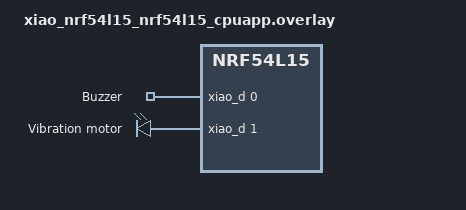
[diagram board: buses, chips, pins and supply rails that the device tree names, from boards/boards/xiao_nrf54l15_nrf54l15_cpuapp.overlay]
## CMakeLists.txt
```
#
# Copyright (c) 2024 Nordic Semiconductor ASA
#
# SPDX-License-Identifier: LicenseRef-Nordic-5-Clause
#
cmake_minimum_required(VERSION 3.20.0)

find_package(Zephyr REQUIRED HINTS $ENV{ZEPHYR_BASE})
project(Emretag)

# NORDIC SDK APP START
target_sources(app PRIVATE
  src/main.c
  src/outputs.c
  src/button.c
  src/imu.c
  src/app_gatt.c
  src/ble_cs.c
)
# NORDIC SDK APP END
```

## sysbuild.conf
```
# MCUboot as an immutable first-stage bootloader.
SB_CONFIG_BOOTLOADER_MCUBOOT=y

# ED25519 over SHA-256. The nRF54L15 has hardware support for it, and it keeps
# the signature small compared with RSA.
SB_CONFIG_BOOT_SIGNATURE_TYPE_ED25519=y

# Swap-using-move keeps the previous image in the other slot, which is what
# makes revert possible: an image that boots but is never confirmed is rolled
# back on the next reset. Overwrite-only would delete the old image and there
# would be nothing to fall back to.
SB_CONFIG_MCUBOOT_MODE_SWAP_USING_MOVE=y

# Until a real key is generated, the build falls back to the MCUboot sample key
# that ships with the SDK - which is public, so it authenticates nothing.
# Generate a private key and point this at it before flashing anything that
# matters:
#
#   imgtool keygen -k mcuboot_signing_key.pem -t ed25519
#
# then uncomment, and keep the .pem out of the repository.
#
# SB_CONFIG_BOOT_SIGNATURE_KEY_FILE="mcuboot_signing_key.pem"
```

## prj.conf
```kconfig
#
# Copyright (c) 2024 Nordic Semiconductor ASA
#
# SPDX-License-Identifier: LicenseRef-Nordic-5-Clause
#

CONFIG_NCS_SAMPLES_DEFAULTS=y
CONFIG_DK_LIBRARY=y

CONFIG_BT=y
CONFIG_BT_PERIPHERAL=y
CONFIG_BT_SMP=y
CONFIG_BT_DEVICE_NAME="EmreTag"
CONFIG_BT_MAX_CONN=1
CONFIG_BT_GAP_AUTO_UPDATE_CONN_PARAMS=n
CONFIG_BT_BONDABLE=n

# The Ranging Profile recommends a MTU of at least 247 octets.
CONFIG_BT_L2CAP_TX_MTU=498
CONFIG_BT_BUF_ACL_TX_SIZE=502
CONFIG_BT_BUF_ACL_RX_SIZE=502
CONFIG_BT_CTLR_DATA_LENGTH_MAX=251
CONFIG_BT_CTLR_PHY_2M=y

# This reduces RAM usage. Additional RAM is needed to support optional
# features such as mode 3 or multiantenna. Change or remove these if
# using those features
CONFIG_BT_RAS_MODE_3_SUPPORTED=n
CONFIG_BT_RAS_MAX_ANTENNA_PATHS=1
CONFIG_BT_CS_DE_MAX_NUM_ANTENNA_PATHS=1
CONFIG_BT_CTLR_SDC_CS_MAX_ANTENNA_PATHS=1
CONFIG_BT_CTLR_SDC_CS_NUM_ANTENNAS=1
CONFIG_BT_CTLR_SDC_CS_STEP_MODE3=n
CONFIG_BT_CTLR_SDC_CS_ROLE_REFLECTOR_ONLY=y

# Disabling the CS Test command reduces flash usage
CONFIG_BT_CTLR_CHANNEL_SOUNDING_TEST=n

# This allows CS and ACL to use different PHYs
CONFIG_BT_TRANSMIT_POWER_CONTROL=y

# Let the initiating device control the PHY updates
CONFIG_BT_AUTO_PHY_UPDATE=n

CONFIG_BT_CHANNEL_SOUNDING=y
CONFIG_BT_RAS=y
CONFIG_BT_RAS_RRSP=y

# IMU. The onboard LSM6DS3TR-C is driven by the LSM6DSL driver (see the
# "st,lsm6dsl" compatible in the board DTS). The driver selects I2C itself.
CONFIG_SENSOR=y
CONFIG_LSM6DSL=y
# Poll the sensor instead of using its INT pin.
CONFIG_LSM6DSL_TRIGGER_NONE=y
# The driver defaults are 0 ("selected at runtime"), which leaves the sensor
# powered down and every reading at zero. 4 = 104 Hz.
CONFIG_LSM6DSL_ACCEL_ODR=4
CONFIG_LSM6DSL_ACCEL_FS=2
CONFIG_LSM6DSL_GYRO_ODR=4
CONFIG_LSM6DSL_GYRO_FS=250

# Required for the %f conversions in the IMU log output.
CONFIG_CBPRINTF_FP_SUPPORT=y

# --- Firmware update over BLE (SMP / MCUmgr): currently disabled ---
#
# Belongs together with the MCUboot block in sysbuild.conf - image upload is
# pointless without a bootloader to hand the new image to. Re-enable both.
#
# CONFIG_MCUMGR=y
# CONFIG_MCUMGR_TRANSPORT_BT=y
#
# With CONFIG_BT_SMP the SMP service defaults to requiring an encrypted and
# authenticated link, which this application cannot provide because it does not
# bond (CONFIG_BT_BONDABLE=n). Left at the default, every DFU attempt fails with
# an ATT authentication error - an hour lost to a symptom that never names its
# cause. Open access is acceptable on a bench device because MCUboot still
# refuses anything not signed with the right key; a shipping product should bond
# and put this back to RW_AUTHEN so the link is trusted too.
#
# CONFIG_MCUMGR_TRANSPORT_BT_PERM_RW=y
# CONFIG_MCUMGR_TRANSPORT_BT_CONN_PARAM_CONTROL=y
#
# CONFIG_MCUMGR_GRP_IMG=y
# CONFIG_MCUMGR_GRP_OS=y
# CONFIG_MCUMGR_GRP_OS_MCUMGR_PARAMS=y
#
# CONFIG_FLASH=y
# CONFIG_FLASH_MAP=y
# CONFIG_STREAM_FLASH=y
# CONFIG_IMG_MANAGER=y
# CONFIG_IMG_ERASE_PROGRESSIVELY=y
# CONFIG_MCUBOOT_IMG_MANAGER=y
```

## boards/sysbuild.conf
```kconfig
# --- Secure boot and DFU: currently disabled ---
#
# Re-enable together with the MCUmgr block in prj.conf; neither half is useful
# on its own. A pristine build is needed either way, because sysbuild only
# collects this file at configure time:
#
#   west build -b xiao_nrf54l15/nrf54l15/cpuapp -p always
#
# MCUboot as an immutable first-stage bootloader:
#
# SB_CONFIG_BOOTLOADER_MCUBOOT=y
#
# ED25519 over SHA-256. The nRF54L15 has hardware support for it, and the
# signature is small compared with RSA.
#
# SB_CONFIG_BOOT_SIGNATURE_TYPE_ED25519=y
#
# Swap-using-move keeps the previous image in the other slot, which is what
# makes revert possible: an image that boots but is never confirmed is rolled
# back on the next reset. Overwrite-only would delete the old image and there
# would be nothing to fall back to.
#
# SB_CONFIG_MCUBOOT_MODE_SWAP_USING_MOVE=y
#
# Without a key file the build falls back to the MCUboot sample key that ships
# with the SDK - which is public, so it authenticates nothing. Generate one and
# keep the .pem out of the repository:
#
#   imgtool keygen -k mcuboot_signing_key.pem -t ed25519
#
# SB_CONFIG_BOOT_SIGNATURE_KEY_FILE="mcuboot_signing_key.pem"
```

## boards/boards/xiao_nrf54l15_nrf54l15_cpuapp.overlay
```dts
/*
 * Buzzer and vibration motor. The board devicetree does not describe them, so
 * the tag adds them here.
 *
 * Pins are XIAO connector numbers (D0..D15), mapped in
 * seeed_xiao_connector.dtsi. CHANGE THESE TO MATCH YOUR WIRING - D0 and D1 are
 * placeholders. Check before using D6..D10 or D13..D15: those land on gpio2,
 * which also carries the LED (pin 0) and the RF switch (pins 3 and 5).
 *
 * Use GPIO_ACTIVE_LOW instead of GPIO_ACTIVE_HIGH if the driver transistor
 * turns the load on when the pin is pulled low. Nothing in the C code needs to
 * change; gpio_pin_set_dt() works in logical levels.
 *
 * "gpio-leds" is used as the compatible because it is Zephyr's generic binding
 * for a set of GPIO outputs - it is not saying these are LEDs.
 */

/ {
	tag_outputs {
		compatible = "gpio-leds";

		buzzer: buzzer {
			gpios = <&xiao_d 0 GPIO_ACTIVE_HIGH>;	/* D0 -> P1.04 */
			label = "Buzzer";
		};

		vibration_motor: vibration-motor {
			gpios = <&xiao_d 1 GPIO_ACTIVE_HIGH>;	/* D1 -> P1.05 */
			label = "Vibration motor";
		};
	};

	aliases {
		buzzer = &buzzer;
		vibration-motor = &vibration_motor;
	};
};
```

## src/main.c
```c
/*
 * Copyright (c) 2024 Nordic Semiconductor ASA
 *
 * SPDX-License-Identifier: LicenseRef-Nordic-5-Clause
 */

/** @file
 *  @brief EmreTag - Channel Sounding reflector with Ranging Responder.
 *
 *  Only the start-up order lives here. Drivers sit in imu.c, button.c and
 *  outputs.c; the link and the Channel Sounding role in ble_cs.c; the
 *  application - the profile and what the tag does - in app_gatt.c.
 */

#include <zephyr/kernel.h>
#include <zephyr/logging/log.h>

#include "app_gatt.h"
#include "ble_cs.h"
#include "outputs.h"

LOG_MODULE_REGISTER(app_main, LOG_LEVEL_INF);

int main(void)
{
	int err;

	LOG_INF("Starting EmreTag - Channel Sounding reflector");

	err = outputs_init();
	if (err) {
		return -1;
	}

	/* Selects the antenna path before bringing the radio up. */
	err = ble_cs_start();
	if (err) {
		return -1;
	}

	/* After advertising is up: from here a button press or a tap can reach
	 * the Bluetooth stack.
	 */
	err = app_gatt_init();
	if (err) {
		return -1;
	}

	ble_cs_run();

	return 0;
}
```

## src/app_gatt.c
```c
/*
 * SPDX-License-Identifier: LicenseRef-Nordic-5-Clause
 */

#include <zephyr/kernel.h>
#include <zephyr/bluetooth/bluetooth.h>
#include <zephyr/bluetooth/gatt.h>
#include <zephyr/bluetooth/uuid.h>
#include <zephyr/logging/log.h>

#include "app_gatt.h"
#include "button.h"
#include "outputs.h"

LOG_MODULE_REGISTER(app_gatt, LOG_LEVEL_INF);

/* Built on the Nordic LED Button Service UUIDs so that nRF Connect and nRF
 * Toolbox recognise the first three characteristics out of the box; the buzzer
 * and vibration motor continue the same series.
 */
#define BT_UUID_BTN_SVC_VAL                                                                        \
	BT_UUID_128_ENCODE(0x00001523, 0x1212, 0xefde, 0x1523, 0x785feabcd123)
#define BT_UUID_BTN_CHRC_VAL                                                                       \
	BT_UUID_128_ENCODE(0x00001524, 0x1212, 0xefde, 0x1523, 0x785feabcd123)
#define BT_UUID_LED_CHRC_VAL                                                                       \
	BT_UUID_128_ENCODE(0x00001525, 0x1212, 0xefde, 0x1523, 0x785feabcd123)
#define BT_UUID_BUZZER_CHRC_VAL                                                                    \
	BT_UUID_128_ENCODE(0x00001526, 0x1212, 0xefde, 0x1523, 0x785feabcd123)
#define BT_UUID_VIB_CHRC_VAL                                                                       \
	BT_UUID_128_ENCODE(0x00001527, 0x1212, 0xefde, 0x1523, 0x785feabcd123)
#define BT_UUID_FIND_PHONE_CHRC_VAL                                                                \
	BT_UUID_128_ENCODE(0x00001528, 0x1212, 0xefde, 0x1523, 0x785feabcd123)
#define BT_UUID_FALL_CHRC_VAL                                                                      \
	BT_UUID_128_ENCODE(0x00001529, 0x1212, 0xefde, 0x1523, 0x785feabcd123)

#define BT_UUID_BTN_SVC     BT_UUID_DECLARE_128(BT_UUID_BTN_SVC_VAL)
#define BT_UUID_BTN_CHRC    BT_UUID_DECLARE_128(BT_UUID_BTN_CHRC_VAL)
#define BT_UUID_LED_CHRC    BT_UUID_DECLARE_128(BT_UUID_LED_CHRC_VAL)
#define BT_UUID_BUZZER_CHRC BT_UUID_DECLARE_128(BT_UUID_BUZZER_CHRC_VAL)
#define BT_UUID_VIB_CHRC    BT_UUID_DECLARE_128(BT_UUID_VIB_CHRC_VAL)
#define BT_UUID_FIND_PHONE_CHRC BT_UUID_DECLARE_128(BT_UUID_FIND_PHONE_CHRC_VAL)
#define BT_UUID_FALL_CHRC	BT_UUID_DECLARE_128(BT_UUID_FALL_CHRC_VAL)

/* Backing store for the button characteristic value. Kept in sync from the
 * notify path so a plain read returns the current level too.
 */
static uint8_t button_value;
static bool button_notify_enabled;

/* Incremented every time the user asks for the phone. Readable as well as
 * notified, so a client that reconnects can see whether it missed anything.
 */
static uint8_t find_phone_count;
static bool find_phone_notify_enabled;

static ssize_t read_button(struct bt_conn *conn, const struct bt_gatt_attr *attr, void *buf,
			   uint16_t len, uint16_t offset)
{
	button_value = button_get_state();

	return bt_gatt_attr_read(conn, attr, buf, len, offset, &button_value,
				 sizeof(button_value));
}

static void button_ccc_cfg_changed(const struct bt_gatt_attr *attr, uint16_t value)
{
	ARG_UNUSED(attr);

	button_notify_enabled = (value == BT_GATT_CCC_NOTIFY);
	LOG_INF("Button notifications %s", button_notify_enabled ? "enabled" : "disabled");
}

static ssize_t read_find_phone(struct bt_conn *conn, const struct bt_gatt_attr *attr, void *buf,
			       uint16_t len, uint16_t offset)
{
	return bt_gatt_attr_read(conn, attr, buf, len, offset, &find_phone_count,
				 sizeof(find_phone_count));
}

/* Same shape as the find-phone counter: raised by the tag, cleared by the peer. */
static uint8_t fall_count;
static bool fall_notify_enabled;
static app_gatt_fall_cleared_cb_t fall_cleared_cb;

/* Defined below the service, which they have to reference. */
static void find_phone_notify_work_handler(struct k_work *work);
static void fall_notify_work_handler(struct k_work *work);

static K_WORK_DEFINE(find_phone_notify_work, find_phone_notify_work_handler);
static K_WORK_DEFINE(fall_notify_work, fall_notify_work_handler);

static ssize_t read_fall(struct bt_conn *conn, const struct bt_gatt_attr *attr, void *buf,
			 uint16_t len, uint16_t offset)
{
	return bt_gatt_attr_read(conn, attr, buf, len, offset, &fall_count, sizeof(fall_count));
}

static ssize_t write_fall(struct bt_conn *conn, const struct bt_gatt_attr *attr, const void *buf,
			  uint16_t len, uint16_t offset, uint8_t flags)
{
	ARG_UNUSED(conn);
	ARG_UNUSED(attr);
	ARG_UNUSED(flags);

	if (offset != 0) {
		return BT_GATT_ERR(BT_ATT_ERR_INVALID_OFFSET);
	}

	if (len != sizeof(fall_count)) {
		return BT_GATT_ERR(BT_ATT_ERR_INVALID_ATTRIBUTE_LEN);
	}

	if (((const uint8_t *)buf)[0] != 0) {
		return BT_GATT_ERR(BT_ATT_ERR_VALUE_NOT_ALLOWED);
	}

	fall_count = 0;
	LOG_INF("Fall alarm cleared by peer");

	if (fall_cleared_cb) {
		fall_cleared_cb();
	}

	k_work_submit(&fall_notify_work);

	return len;
}

static void fall_ccc_cfg_changed(const struct bt_gatt_attr *attr, uint16_t value)
{
	ARG_UNUSED(attr);

	fall_notify_enabled = (value == BT_GATT_CCC_NOTIFY);
	LOG_INF("Fall notifications %s", fall_notify_enabled ? "enabled" : "disabled");
}

/* The phone writes 0 to say it has handled - or dismissed - the request, which
 * clears the counter. Any other value is refused, so the count can only ever be
 * raised by the tag itself.
 */
static ssize_t write_find_phone(struct bt_conn *conn, const struct bt_gatt_attr *attr,
				const void *buf, uint16_t len, uint16_t offset, uint8_t flags)
{
	ARG_UNUSED(conn);
	ARG_UNUSED(attr);
	ARG_UNUSED(flags);

	if (offset != 0) {
		return BT_GATT_ERR(BT_ATT_ERR_INVALID_OFFSET);
	}

	if (len != sizeof(find_phone_count)) {
		return BT_GATT_ERR(BT_ATT_ERR_INVALID_ATTRIBUTE_LEN);
	}

	if (((const uint8_t *)buf)[0] != 0) {
		return BT_GATT_ERR(BT_ATT_ERR_VALUE_NOT_ALLOWED);
	}

	find_phone_count = 0;
	LOG_INF("Find-phone cancelled by peer");

	/* Push the cleared value out, otherwise a client that follows the
	 * characteristic through notifications keeps showing the old count until
	 * it happens to read again. Deferred, so the write response goes out
	 * before the notification.
	 */
	k_work_submit(&find_phone_notify_work);

	return len;
}

static void find_phone_ccc_cfg_changed(const struct bt_gatt_attr *attr, uint16_t value)
{
	ARG_UNUSED(attr);

	find_phone_notify_enabled = (value == BT_GATT_CCC_NOTIFY);
	LOG_INF("Find-phone notifications %s", find_phone_notify_enabled ? "enabled" : "disabled");
}

static ssize_t read_output(struct bt_conn *conn, const struct bt_gatt_attr *attr, void *buf,
			   uint16_t len, uint16_t offset)
{
	const struct gpio_output *out = attr->user_data;

	return bt_gatt_attr_read(conn, attr, buf, len, offset, &out->state, sizeof(out->state));
}

static ssize_t write_output(struct bt_conn *conn, const struct bt_gatt_attr *attr, const void *buf,
			    uint16_t len, uint16_t offset, uint8_t flags)
{
	struct gpio_output *out = attr->user_data;

	ARG_UNUSED(conn);
	ARG_UNUSED(flags);

	if (offset != 0) {
		return BT_GATT_ERR(BT_ATT_ERR_INVALID_OFFSET);
	}

	if (len != sizeof(out->state)) {
		return BT_GATT_ERR(BT_ATT_ERR_INVALID_ATTRIBUTE_LEN);
	}

	outputs_set(out, ((const uint8_t *)buf)[0]);

	LOG_INF("%s set to %u by peer", out->name, out->state);

	return len;
}

/* Each characteristic carries a User Description descriptor (0x2901) so that a
 * generic GATT client shows a name instead of just the 128-bit UUID. The button
 * value stays at attrs[2] - descriptors are appended after it, never before.
 */
BT_GATT_SERVICE_DEFINE(app_svc,
	BT_GATT_PRIMARY_SERVICE(BT_UUID_BTN_SVC),

	BT_GATT_CHARACTERISTIC(BT_UUID_BTN_CHRC,
			       BT_GATT_CHRC_READ | BT_GATT_CHRC_NOTIFY,
			       BT_GATT_PERM_READ,
			       read_button, NULL, &button_value),
	BT_GATT_CCC(button_ccc_cfg_changed, BT_GATT_PERM_READ | BT_GATT_PERM_WRITE),
	BT_GATT_CUD("Button", BT_GATT_PERM_READ),

	BT_GATT_CHARACTERISTIC(BT_UUID_LED_CHRC,
			       BT_GATT_CHRC_READ | BT_GATT_CHRC_WRITE,
			       BT_GATT_PERM_READ | BT_GATT_PERM_WRITE,
			       read_output, write_output, &led),
	BT_GATT_CUD("LED", BT_GATT_PERM_READ),

	BT_GATT_CHARACTERISTIC(BT_UUID_BUZZER_CHRC,
			       BT_GATT_CHRC_READ | BT_GATT_CHRC_WRITE,
			       BT_GATT_PERM_READ | BT_GATT_PERM_WRITE,
			       read_output, write_output, &buzzer),
	BT_GATT_CUD("Buzzer", BT_GATT_PERM_READ),

	BT_GATT_CHARACTERISTIC(BT_UUID_VIB_CHRC,
			       BT_GATT_CHRC_READ | BT_GATT_CHRC_WRITE,
			       BT_GATT_PERM_READ | BT_GATT_PERM_WRITE,
			       read_output, write_output, &vibration_motor),
	BT_GATT_CUD("Vibration motor", BT_GATT_PERM_READ),

	BT_GATT_CHARACTERISTIC(BT_UUID_FIND_PHONE_CHRC,
			       BT_GATT_CHRC_READ | BT_GATT_CHRC_WRITE | BT_GATT_CHRC_NOTIFY,
			       BT_GATT_PERM_READ | BT_GATT_PERM_WRITE,
			       read_find_phone, write_find_phone, &find_phone_count),
	BT_GATT_CCC(find_phone_ccc_cfg_changed, BT_GATT_PERM_READ | BT_GATT_PERM_WRITE),
	BT_GATT_CUD("Find phone", BT_GATT_PERM_READ),

	BT_GATT_CHARACTERISTIC(BT_UUID_FALL_CHRC,
			       BT_GATT_CHRC_READ | BT_GATT_CHRC_WRITE | BT_GATT_CHRC_NOTIFY,
			       BT_GATT_PERM_READ | BT_GATT_PERM_WRITE,
			       read_fall, write_fall, &fall_count),
	BT_GATT_CCC(fall_ccc_cfg_changed, BT_GATT_PERM_READ | BT_GATT_PERM_WRITE),
	BT_GATT_CUD("Fall detected", BT_GATT_PERM_READ),
);

int app_gatt_notify_button(uint8_t state)
{
	if (!button_notify_enabled) {
		return 0;
	}

	button_value = state;

	/* attrs[2] is the button characteristic value attribute. */
	return bt_gatt_notify(NULL, &app_svc.attrs[2], &button_value, sizeof(button_value));
}

/* Sends whatever the counter currently holds to a subscribed client. */
static int notify_find_phone_value(void)
{
	const struct bt_gatt_attr *attr;

	if (!find_phone_notify_enabled) {
		return 0;
	}

	/* Looked up rather than indexed, so inserting characteristics above it
	 * cannot silently point this at the wrong attribute.
	 */
	attr = bt_gatt_find_by_uuid(app_svc.attrs, app_svc.attr_count, BT_UUID_FIND_PHONE_CHRC);
	if (!attr) {
		return -ENOENT;
	}

	return bt_gatt_notify(NULL, attr, &find_phone_count, sizeof(find_phone_count));
}

static void find_phone_notify_work_handler(struct k_work *work)
{
	int err;

	ARG_UNUSED(work);

	err = notify_find_phone_value();
	if (err) {
		LOG_WRN("Failed to notify find-phone value (err %d)", err);
	}
}

int app_gatt_notify_find_phone(void)
{
	find_phone_count++;

	return notify_find_phone_value();
}

static int notify_fall_value(void)
{
	const struct bt_gatt_attr *attr;

	if (!fall_notify_enabled) {
		return 0;
	}

	attr = bt_gatt_find_by_uuid(app_svc.attrs, app_svc.attr_count, BT_UUID_FALL_CHRC);
	if (!attr) {
		return -ENOENT;
	}

	return bt_gatt_notify(NULL, attr, &fall_count, sizeof(fall_count));
}

static void fall_notify_work_handler(struct k_work *work)
{
	int err;

	ARG_UNUSED(work);

	err = notify_fall_value();
	if (err) {
		LOG_WRN("Failed to notify fall value (err %d)", err);
	}
}

void app_gatt_set_fall_cleared_cb(app_gatt_fall_cleared_cb_t cb)
{
	fall_cleared_cb = cb;
}

int app_gatt_notify_fall(void)
{
	fall_count++;

	return notify_fall_value();
}
```

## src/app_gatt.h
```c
/*
 * SPDX-License-Identifier: LicenseRef-Nordic-5-Clause
 */

/** @file
 *  @brief Application GATT service - button state in, output control out.
 *
 *  Distance values are not carried here; those go over the Ranging Service
 *  (RAS) provided by the nRF Connect SDK.
 */

#ifndef APP_GATT_H_
#define APP_GATT_H_

#include <stdint.h>

/** Notify the subscribed peer of a new button state.
 *
 *  Sends an HCI command and can block, so do not call from interrupt context.
 *  A no-op when no client has enabled notifications.
 */
int app_gatt_notify_button(uint8_t state);

/** Ask the connected phone to make itself findable.
 *
 *  Bumps a counter and notifies it, so a client can also see how many requests
 *  it missed. The phone clears the counter back to zero by writing 0 to the
 *  characteristic once it has handled or dismissed the request.
 *
 *  Sends an HCI command and can block; not for interrupt context.
 */
int app_gatt_notify_find_phone(void);

/** Called from the Bluetooth thread when the peer clears the fall alarm. */
typedef void (*app_gatt_fall_cleared_cb_t)(void);

/** Register who should be told that the peer cleared the fall alarm. */
void app_gatt_set_fall_cleared_cb(app_gatt_fall_cleared_cb_t cb);

/** Report that the tag has been dropped.
 *
 *  Same shape as the find-phone characteristic: a counter the peer clears by
 *  writing 0, which also stops the local alarm.
 */
int app_gatt_notify_fall(void);

#endif /* APP_GATT_H_ */
```

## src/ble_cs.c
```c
/*
 * SPDX-License-Identifier: LicenseRef-Nordic-5-Clause
 */

#include <zephyr/kernel.h>
#include <zephyr/bluetooth/bluetooth.h>
#include <zephyr/bluetooth/conn.h>
#include <zephyr/bluetooth/cs.h>
#include <zephyr/bluetooth/gap.h>
#include <zephyr/bluetooth/uuid.h>
#include <zephyr/settings/settings.h>
#include <zephyr/sys/byteorder.h>
#include <zephyr/sys/reboot.h>
#include <zephyr/logging/log.h>

#include <bluetooth/services/ras.h>

#include "ble_cs.h"
#include "outputs.h"

LOG_MODULE_REGISTER(ble_cs, LOG_LEVEL_INF);

#define COMPANY_ID_CODE 0x0059

static K_SEM_DEFINE(sem_connected, 0, 1);
static K_SEM_DEFINE(sem_config, 0, 1);

static struct bt_conn *connection;

struct adv_mfg_data {
	uint16_t company_code;	/* Company Identifier Code. */
	uint16_t number_press;	/* Number of times the button was pressed. */
};

static struct adv_mfg_data adv_mfg_data = { COMPANY_ID_CODE, 0x00 };

static const struct bt_data ad[] = {
	BT_DATA_BYTES(BT_DATA_FLAGS, (BT_LE_AD_GENERAL | BT_LE_AD_NO_BREDR)),
	BT_DATA_BYTES(BT_DATA_UUID16_ALL, BT_UUID_16_ENCODE(BT_UUID_RANGING_SERVICE_VAL)),
	BT_DATA(BT_DATA_NAME_COMPLETE, CONFIG_BT_DEVICE_NAME, sizeof(CONFIG_BT_DEVICE_NAME) - 1),
	BT_DATA(BT_DATA_MANUFACTURER_DATA, (unsigned char *)&adv_mfg_data, sizeof(adv_mfg_data)),
};

/* 0x17 is the "https://" URI scheme prefix. */
static const unsigned char url_data[] = { 0x17, '/', '/', 'g', 'i', 't', 'h', 'u', 'b', '.', 'c',
					  'o', 'm', '/', 'E', 'm', 'r', 'e', 'c', 'a', 'n', 'b',
					  'l' };

static const struct bt_data sd[] = {
	BT_DATA(BT_DATA_URI, url_data, sizeof(url_data)),
};

static void connected_cb(struct bt_conn *conn, uint8_t err)
{
	char addr[BT_ADDR_LE_STR_LEN];

	(void)bt_addr_le_to_str(bt_conn_get_dst(conn), addr, sizeof(addr));
	LOG_INF("Connected to %s (err 0x%02X)", addr, err);

	if (err) {
		bt_conn_unref(conn);
		connection = NULL;
	} else {
		connection = bt_conn_ref(conn);

		k_sem_give(&sem_connected);

		outputs_set(&led, 1);
	}
}

static void disconnected_cb(struct bt_conn *conn, uint8_t reason)
{
	LOG_INF("Disconnected (reason 0x%02X)", reason);

	bt_conn_unref(conn);
	connection = NULL;

	outputs_set(&led, 0);

	/* Inherited from the upstream Channel Sounding sample: a cold reboot
	 * sidesteps tearing the CS state down by hand. Incompatible with the
	 * low-power design and has to go once teardown is handled properly.
	 */
	sys_reboot(SYS_REBOOT_COLD);
}

static void remote_capabilities_cb(struct bt_conn *conn, uint8_t status,
				   struct bt_conn_le_cs_capabilities *params)
{
	ARG_UNUSED(conn);
	ARG_UNUSED(params);

	if (status == BT_HCI_ERR_SUCCESS) {
		LOG_INF("CS capability exchange completed.");
	} else {
		LOG_WRN("CS capability exchange failed. (HCI status 0x%02x)", status);
	}
}

static void config_create_cb(struct bt_conn *conn, uint8_t status,
			     struct bt_conn_le_cs_config *config)
{
	ARG_UNUSED(conn);

	if (status != BT_HCI_ERR_SUCCESS) {
		LOG_WRN("CS config creation failed. (HCI status 0x%02x)", status);
		return;
	}

	const char *mode_str[5] = { "Unused", "1 (RTT)", "2 (PBR)", "3 (RTT + PBR)", "Invalid" };
	const char *role_str[3] = { "Initiator", "Reflector", "Invalid" };
	const char *rtt_type_str[8] = { "AA only",	 "32-bit sounding", "96-bit sounding",
					"32-bit random", "64-bit random",   "96-bit random",
					"128-bit random", "Invalid" };
	const char *phy_str[4] = { "Invalid", "LE 1M PHY", "LE 2M PHY", "LE 2M 2BT PHY" };
	const char *chsel_type_str[3] = { "Algorithm #3b", "Algorithm #3c", "Invalid" };
	const char *ch3c_shape_str[3] = { "Hat shape", "X shape", "Invalid" };

	uint8_t mode_idx = config->mode > 0 && config->mode < 4 ? config->mode : 4;
	uint8_t role_idx = MIN(config->role, 2);
	uint8_t rtt_type_idx = MIN(config->rtt_type, 7);
	uint8_t phy_idx = config->cs_sync_phy > 0 && config->cs_sync_phy < 4 ? config->cs_sync_phy
									    : 0;
	uint8_t chsel_type_idx = MIN(config->channel_selection_type, 2);
	uint8_t ch3c_shape_idx = MIN(config->ch3c_shape, 2);

	LOG_INF("CS config creation complete.\n"
		" - id: %u\n"
		" - mode: %s\n"
		" - min_main_mode_steps: %u\n"
		" - max_main_mode_steps: %u\n"
		" - main_mode_repetition: %u\n"
		" - mode_0_steps: %u\n"
		" - role: %s\n"
		" - rtt_type: %s\n"
		" - cs_sync_phy: %s\n"
		" - channel_map_repetition: %u\n"
		" - channel_selection_type: %s\n"
		" - ch3c_shape: %s\n"
		" - ch3c_jump: %u\n"
		" - t_ip1_time_us: %u\n"
		" - t_ip2_time_us: %u\n"
		" - t_fcs_time_us: %u\n"
		" - t_pm_time_us: %u\n"
		" - channel_map: 0x%08X%08X%04X\n",
		config->id, mode_str[mode_idx], config->min_main_mode_steps,
		config->max_main_mode_steps, config->main_mode_repetition, config->mode_0_steps,
		role_str[role_idx], rtt_type_str[rtt_type_idx], phy_str[phy_idx],
		config->channel_map_repetition, chsel_type_str[chsel_type_idx],
		ch3c_shape_str[ch3c_shape_idx], config->ch3c_jump, config->t_ip1_time_us,
		config->t_ip2_time_us, config->t_fcs_time_us, config->t_pm_time_us,
		sys_get_le32(&config->channel_map[6]), sys_get_le32(&config->channel_map[2]),
		sys_get_le16(&config->channel_map[0]));

	k_sem_give(&sem_config);
}

static void security_enable_cb(struct bt_conn *conn, uint8_t status)
{
	ARG_UNUSED(conn);

	if (status == BT_HCI_ERR_SUCCESS) {
		LOG_INF("CS security enabled.");
	} else {
		LOG_WRN("CS security enable failed. (HCI status 0x%02x)", status);
	}
}

static void procedure_enable_cb(struct bt_conn *conn, uint8_t status,
				struct bt_conn_le_cs_procedure_enable_complete *params)
{
	ARG_UNUSED(conn);

	if (status != BT_HCI_ERR_SUCCESS) {
		LOG_WRN("CS procedures enable failed. (HCI status 0x%02x)", status);
		return;
	}

	if (params->state != 1) {
		LOG_INF("CS procedures disabled.");
		return;
	}

	LOG_INF("CS procedures enabled:\n"
		" - config ID: %u\n"
		" - antenna configuration index: %u\n"
		" - TX power: %d dbm\n"
		" - subevent length: %u us\n"
		" - subevents per event: %u\n"
		" - subevent interval: %u\n"
		" - event interval: %u\n"
		" - procedure interval: %u\n"
		" - procedure count: %u\n"
		" - maximum procedure length: %u",
		params->config_id, params->tone_antenna_config_selection,
		params->selected_tx_power, params->subevent_len, params->subevents_per_event,
		params->subevent_interval, params->event_interval, params->procedure_interval,
		params->procedure_count, params->max_procedure_len);
}

BT_CONN_CB_DEFINE(conn_cb) = {
	.connected = connected_cb,
	.disconnected = disconnected_cb,
	.le_cs_read_remote_capabilities_complete = remote_capabilities_cb,
	.le_cs_config_complete = config_create_cb,
	.le_cs_security_enable_complete = security_enable_cb,
	.le_cs_procedure_enable_complete = procedure_enable_cb,
};

int ble_cs_start(void)
{
	int err;

	err = bt_enable(NULL);
	if (err) {
		LOG_ERR("Bluetooth init failed (err %d)", err);
		return err;
	}

	if (IS_ENABLED(CONFIG_BT_SETTINGS)) {
		settings_load();
	}

	err = bt_le_adv_start(BT_LE_ADV_CONN_FAST_2, ad, ARRAY_SIZE(ad), sd, ARRAY_SIZE(sd));
	if (err) {
		LOG_ERR("Advertising failed to start (err %d)", err);
		return err;
	}

	return 0;
}

int ble_cs_set_press_count(uint16_t count)
{
	adv_mfg_data.number_press = count;

	return bt_le_adv_update_data(ad, ARRAY_SIZE(ad), sd, ARRAY_SIZE(sd));
}

void ble_cs_run(void)
{
	while (true) {
		int err;

		k_sem_take(&sem_connected, K_FOREVER);

		const struct bt_le_cs_set_default_settings_param default_settings = {
			.enable_initiator_role = false,
			.enable_reflector_role = true,
			.cs_sync_antenna_selection = BT_LE_CS_ANTENNA_SELECTION_OPT_REPETITIVE,
			.max_tx_power = BT_HCI_OP_LE_CS_MAX_MAX_TX_POWER,
		};

		err = bt_le_cs_set_default_settings(connection, &default_settings);
		if (err) {
			LOG_ERR("Failed to configure default CS settings (err %d)", err);
			continue;
		}

		k_sem_take(&sem_config, K_FOREVER);

		const struct bt_le_cs_set_procedure_parameters_param procedure_params = {
			.config_id = 0,
			.max_procedure_len = 1000,
			.min_procedure_interval = 1,
			.max_procedure_interval = 100,
			.max_procedure_count = 0,
			.min_subevent_len = 10000,
			.max_subevent_len = 75000,
			.tone_antenna_config_selection = BT_LE_CS_TONE_ANTENNA_CONFIGURATION_A1_B1,
			.phy = BT_LE_CS_PROCEDURE_PHY_2M,
			.tx_power_delta = 0x80,
			.preferred_peer_antenna = BT_LE_CS_PROCEDURE_PREFERRED_PEER_ANTENNA_1,
			.snr_control_initiator = BT_LE_CS_SNR_CONTROL_NOT_USED,
			.snr_control_reflector = BT_LE_CS_SNR_CONTROL_NOT_USED,
		};

		err = bt_le_cs_set_procedure_parameters(connection, &procedure_params);
		if (err) {
			LOG_ERR("Failed to set procedure parameters (err %d)", err);
		}
	}
}
```

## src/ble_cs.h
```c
/*
 * SPDX-License-Identifier: LicenseRef-Nordic-5-Clause
 */

/** @file
 *  @brief Bluetooth bring-up, advertising and Channel Sounding reflector role.
 */

#ifndef BLE_CS_H_
#define BLE_CS_H_

#include <stdint.h>

/** Enable the Bluetooth stack, load settings and start advertising. */
int ble_cs_start(void);

/** Publish a new button press count in the manufacturer-specific advertising
 *  data and refresh the advertising payload.
 *
 *  Sends an HCI command and can block, so do not call from interrupt context.
 */
int ble_cs_set_press_count(uint16_t count);

/** Configure the Channel Sounding reflector for each incoming connection.
 *
 *  Blocks forever; call it last from main().
 */
void ble_cs_run(void);

#endif /* BLE_CS_H_ */
```

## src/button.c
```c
/*
 * SPDX-License-Identifier: LicenseRef-Nordic-5-Clause
 */

#include <zephyr/kernel.h>
#include <zephyr/drivers/gpio.h>
#include <zephyr/logging/log.h>

#include "button.h"

LOG_MODULE_REGISTER(button, LOG_LEVEL_INF);

#define SW0_NODE DT_ALIAS(sw0)

static const struct gpio_dt_spec button = GPIO_DT_SPEC_GET(SW0_NODE, gpios);
static struct gpio_callback button_cb_data;

static button_cb_t user_cb;

/* 1 while the button is held down, 0 once it is released. */
static volatile uint8_t button_state;
static volatile uint16_t press_count;

/* The GATT and advertising calls the application makes from the callback can
 * block, so they must not run in the GPIO ISR. The ISR only samples the pin and
 * hands off to the work queue; the press count is incremented there too, so no
 * press is lost when several arrive before the work item gets to run.
 */
static void button_work_handler(struct k_work *work)
{
	ARG_UNUSED(work);

	if (user_cb) {
		user_cb(button_state, press_count);
	}
}

static K_WORK_DEFINE(button_work, button_work_handler);

static void button_isr(const struct device *port, struct gpio_callback *cb, uint32_t pins)
{
	ARG_UNUSED(port);
	ARG_UNUSED(cb);
	ARG_UNUSED(pins);

	/* Logical level: 1 when pressed, regardless of the active-low wiring. */
	button_state = (gpio_pin_get_dt(&button) > 0) ? 1 : 0;

	if (button_state) {
		press_count++;
	}

	k_work_submit(&button_work);
}

int button_init(button_cb_t cb)
{
	int err;

	user_cb = cb;

	if (!gpio_is_ready_dt(&button)) {
		LOG_ERR("Button GPIO port is not ready");
		return -ENODEV;
	}

	err = gpio_pin_configure_dt(&button, GPIO_INPUT);
	if (err) {
		LOG_ERR("Failed to configure button pin (err %d)", err);
		return err;
	}

	/* Both edges, otherwise the release is never seen and the reported state
	 * would stay stuck at 1.
	 */
	err = gpio_pin_interrupt_configure_dt(&button, GPIO_INT_EDGE_BOTH);
	if (err) {
		LOG_ERR("Failed to configure button interrupt (err %d)", err);
		return err;
	}

	gpio_init_callback(&button_cb_data, button_isr, BIT(button.pin));

	err = gpio_add_callback_dt(&button, &button_cb_data);
	if (err) {
		LOG_ERR("Failed to add button callback (err %d)", err);
		return err;
	}

	return 0;
}

uint8_t button_get_state(void)
{
	return button_state;
}

uint16_t button_get_press_count(void)
{
	return press_count;
}
```

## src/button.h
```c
/*
 * SPDX-License-Identifier: LicenseRef-Nordic-5-Clause
 */

/** @file
 *  @brief User button (sw0) input.
 */

#ifndef BUTTON_H_
#define BUTTON_H_

#include <stdint.h>

/** Button change callback.
 *
 *  Invoked from the system work queue - never from interrupt context - so it
 *  may call blocking Bluetooth APIs.
 *
 *  @param state       1 while the button is held down, 0 once released.
 *  @param press_count Number of presses since boot.
 */
typedef void (*button_cb_t)(uint8_t state, uint16_t press_count);

/** Configure sw0 as an interrupt-driven input.
 *
 *  Call this only once the rest of the system can cope with @p cb firing.
 */
int button_init(button_cb_t cb);

/** 1 while the button is held down, 0 once released. */
uint8_t button_get_state(void);

/** Number of presses since boot. */
uint16_t button_get_press_count(void);

#endif /* BUTTON_H_ */
```

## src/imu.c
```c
/*
 * SPDX-License-Identifier: LicenseRef-Nordic-5-Clause
 */

#include <zephyr/kernel.h>
#include <zephyr/init.h>
#include <zephyr/drivers/gpio.h>
#include <zephyr/drivers/i2c.h>
#include <zephyr/drivers/regulator.h>
#include <zephyr/drivers/sensor.h>
#include <zephyr/logging/log.h>

#include "imu.h"

LOG_MODULE_REGISTER(imu, LOG_LEVEL_INF);

#define IMU_NODE DT_ALIAS(imu0)

#define IMU_SAMPLE_INTERVAL_MS 500
#define IMU_STACK_SIZE	       2048
#define IMU_PRIORITY	       7

/* Exponential moving average weight applied to each new reading. 1.0 disables
 * filtering; smaller values smooth harder at the cost of response time.
 */
#define IMU_FILTER_ALPHA 0.3

/* Log every sample. Turn this off once something else consumes the data. */
#define IMU_LOG_SAMPLES 1

static const struct device *const imu = DEVICE_DT_GET(IMU_NODE);

/* The IMU and the PDM microphone share a supply rail switched by P0.01 through
 * the pdm_imu_pwr regulator. The board DTS marks it regulator-boot-on, but the
 * same is true of the RF switch nodes and those still needed an explicit
 * enable, so do not rely on it here either.
 *
 * This has to run before the sensor driver probes the chip over I2C, otherwise
 * the WHO_AM_I read fails and the device stays permanently un-ready - enabling
 * the rail from main() would be far too late. POST_KERNEL 60 sits after I2C
 * (50) and before the sensors (CONFIG_SENSOR_INIT_PRIORITY, 90).
 */
static const struct device *const imu_pwr = DEVICE_DT_GET(DT_NODELABEL(pdm_imu_pwr));

static int imu_power_on(void)
{
	int err;

	if (!device_is_ready(imu_pwr)) {
		LOG_ERR("IMU regulator is not ready");
		return -ENODEV;
	}

	err = regulator_enable(imu_pwr);
	if (err) {
		LOG_ERR("Failed to enable the IMU regulator (err %d)", err);
		return err;
	}

	/* regulator_enable() already honours the 5 ms startup-delay-us from the
	 * DTS; this covers the sensor's own power-on boot time on top of it.
	 */
	k_msleep(20);

	return 0;
}

SYS_INIT(imu_power_on, POST_KERNEL, 60);

static struct k_mutex sample_lock;
static struct imu_sample latest;
static bool have_sample;
static bool sensor_ready;

static void filter_axis(double *state, double raw, bool first)
{
	*state = first ? raw : (IMU_FILTER_ALPHA * raw) + ((1.0 - IMU_FILTER_ALPHA) * *state);
}

static void store_sample(const struct sensor_value accel[3], const struct sensor_value gyro[3])
{
	bool first;

	k_mutex_lock(&sample_lock, K_FOREVER);

	first = !have_sample;

	for (int i = 0; i < 3; i++) {
		filter_axis(&latest.accel[i], sensor_value_to_double(&accel[i]), first);
		filter_axis(&latest.gyro[i], sensor_value_to_double(&gyro[i]), first);
	}

	latest.uptime_ms = k_uptime_get();
	have_sample = true;

	k_mutex_unlock(&sample_lock);
}

int imu_get_latest(struct imu_sample *out)
{
	int err = 0;

	k_mutex_lock(&sample_lock, K_FOREVER);

	if (have_sample) {
		*out = latest;
	} else {
		err = -EAGAIN;
	}

	k_mutex_unlock(&sample_lock);

	return err;
}

bool imu_is_ready(void)
{
	return sensor_ready;
}

/* The sensor is polled rather than driven from its INT line, so this runs in
 * its own thread and does not disturb the Bluetooth work queues.
 */
static void imu_thread_fn(void *p1, void *p2, void *p3)
{
	struct sensor_value accel[3];
	struct sensor_value gyro[3];

	ARG_UNUSED(p1);
	ARG_UNUSED(p2);
	ARG_UNUSED(p3);

	k_mutex_init(&sample_lock);

	if (!device_is_ready(imu)) {
		LOG_ERR("IMU %s is not ready", imu->name);
		return;
	}

	sensor_ready = true;
	LOG_INF("IMU %s ready, sampling every %d ms", imu->name, IMU_SAMPLE_INTERVAL_MS);

	while (true) {
		int err = sensor_sample_fetch(imu);

		if (err) {
			LOG_ERR("IMU sample fetch failed (err %d)", err);
			k_msleep(IMU_SAMPLE_INTERVAL_MS);
			continue;
		}

		err = sensor_channel_get(imu, SENSOR_CHAN_ACCEL_XYZ, accel);
		if (err) {
			LOG_ERR("Failed to read acceleration (err %d)", err);
			k_msleep(IMU_SAMPLE_INTERVAL_MS);
			continue;
		}

		err = sensor_channel_get(imu, SENSOR_CHAN_GYRO_XYZ, gyro);
		if (err) {
			LOG_ERR("Failed to read angular velocity (err %d)", err);
			k_msleep(IMU_SAMPLE_INTERVAL_MS);
			continue;
		}

		store_sample(accel, gyro);

#if IMU_LOG_SAMPLES
		LOG_INF("accel %7.3f %7.3f %7.3f m/s2   gyro %7.3f %7.3f %7.3f rad/s",
			latest.accel[0], latest.accel[1], latest.accel[2],
			latest.gyro[0], latest.gyro[1], latest.gyro[2]);
#endif

		k_msleep(IMU_SAMPLE_INTERVAL_MS);
	}
}

K_THREAD_DEFINE(imu_thread, IMU_STACK_SIZE, imu_thread_fn, NULL, NULL, NULL, IMU_PRIORITY, 0, 0);

static const struct i2c_dt_spec imu_i2c = I2C_DT_SPEC_GET(IMU_NODE);
static const struct gpio_dt_spec imu_int = GPIO_DT_SPEC_GET(IMU_NODE, irq_gpios);
static struct gpio_callback imu_int_cb_data;

static imu_event_cb_t event_cb;
static struct imu_motion_config motion_cfg;

static void report(enum imu_event event)
{
	if (event_cb) {
		event_cb(event);
	}
}

/* Reading the source registers needs I2C, which cannot run in the ISR. Reading
 * them is also what clears the latched interrupt (TAP_CFG.LIR), so this must
 * run for the pin to be released.
 */
static void imu_int_work_handler(struct k_work *work)
{
	uint8_t wake_src;
	uint8_t tap_src;
	int err;

	ARG_UNUSED(work);

	err = i2c_reg_read_byte_dt(&imu_i2c, LSM6_REG_WAKE_UP_SRC, &wake_src);
	if (err) {
		LOG_ERR("Failed to read WAKE_UP_SRC (err %d)", err);
		return;
	}

	err = i2c_reg_read_byte_dt(&imu_i2c, LSM6_REG_TAP_SRC, &tap_src);
	if (err) {
		LOG_ERR("Failed to read TAP_SRC (err %d)", err);
		return;
	}

	if (wake_src & LSM6_WAKE_UP_SRC_FF_IA) {
		report(IMU_EVENT_FREE_FALL);
	}

	if (motion_cfg.inactivity_mode != IMU_INACTIVITY_OFF &&
	    (wake_src & LSM6_WAKE_UP_SRC_SLEEP_STATE_IA)) {
		report(IMU_EVENT_INACTIVE);
	}

	/* A double tap sets the single-tap bit too, so check double first and
	 * only fall through when single taps are actually wanted.
	 */
	if (motion_cfg.detect_double_tap && (tap_src & LSM6_TAP_SRC_DOUBLE_TAP)) {
		report(IMU_EVENT_DOUBLE_TAP);
	} else if (motion_cfg.detect_single_tap && (tap_src & LSM6_TAP_SRC_SINGLE_TAP)) {
		report(IMU_EVENT_SINGLE_TAP);
	}

	if (wake_src & LSM6_WAKE_UP_SRC_WU_IA) {
		report(IMU_EVENT_WAKE_UP);
	}
}

static K_WORK_DEFINE(imu_int_work, imu_int_work_handler);

static void imu_int_isr(const struct device *port, struct gpio_callback *cb, uint32_t pins)
{
	ARG_UNUSED(port);
	ARG_UNUSED(cb);
	ARG_UNUSED(pins);

	k_work_submit(&imu_int_work);
}

int imu_motion_detect_enable(imu_event_cb_t cb, const struct imu_motion_config *cfg)
{
	uint8_t tap_cfg;
	uint8_t wake_ths;
	uint8_t wake_dur;
	uint8_t md1;
	int err;

	event_cb = cb;
	motion_cfg = *cfg;

	if (!device_is_ready(imu_i2c.bus)) {
		LOG_ERR("IMU I2C bus is not ready");
		return -ENODEV;
	}

	if (!gpio_is_ready_dt(&imu_int)) {
		LOG_ERR("IMU interrupt GPIO port is not ready");
		return -ENODEV;
	}

	/* Enable the interrupt engines and the tap detector on all three axes,
	 * high-pass the accelerometer data so gravity does not count towards the
	 * threshold, and latch the interrupt until the source register is read.
	 */
	tap_cfg = LSM6_TAP_CFG_INTERRUPTS_ENABLE | LSM6_TAP_CFG_SLOPE_FDS |
		  LSM6_TAP_CFG_TAP_X_EN | LSM6_TAP_CFG_TAP_Y_EN | LSM6_TAP_CFG_TAP_Z_EN |
		  LSM6_TAP_CFG_LIR;
	tap_cfg |= (cfg->inactivity_mode & LSM6_TAP_CFG_INACT_EN_MASK)
		   << LSM6_TAP_CFG_INACT_EN_SHIFT; // 

	err = i2c_reg_write_byte_dt(&imu_i2c, LSM6_REG_TAP_CFG, tap_cfg);
	if (err) {
		LOG_ERR("Failed to write TAP_CFG (err %d)", err);
		return err;
	}

	err = i2c_reg_write_byte_dt(&imu_i2c, LSM6_REG_TAP_THS_6D,
				    cfg->tap_threshold & LSM6_TAP_THS_6D_MASK);
	if (err) {
		LOG_ERR("Failed to write TAP_THS_6D (err %d)", err);
		return err;
	}

	err = i2c_reg_write_byte_dt(&imu_i2c, LSM6_REG_INT_DUR2, LSM6_INT_DUR2_DEFAULT);
	if (err) {
		LOG_ERR("Failed to write INT_DUR2 (err %d)", err);
		return err;
	}

	/* The double-tap detector only runs while SINGLE_DOUBLE_TAP is set; with
	 * it cleared the chip reports single taps only. Single taps are silenced
	 * by not routing them to INT1 below, not by clearing this bit.
	 */
	wake_ths = cfg->wake_threshold & LSM6_WAKE_UP_THS_MASK;
	if (cfg->detect_double_tap) {
		wake_ths |= LSM6_WAKE_UP_THS_SINGLE_DOUBLE_TAP;
	}

	err = i2c_reg_write_byte_dt(&imu_i2c, LSM6_REG_WAKE_UP_THS, wake_ths);
	if (err) {
		LOG_ERR("Failed to write WAKE_UP_THS (err %d)", err);
		return err;
	}

	wake_dur = ((cfg->wake_duration & LSM6_WAKE_UP_DUR_WAKE_MASK)
		    << LSM6_WAKE_UP_DUR_WAKE_SHIFT) |
		   (cfg->inactivity_duration & LSM6_WAKE_UP_DUR_SLEEP_MASK);

	/* The sixth bit of the free-fall duration lives here, not in FREE_FALL. */
	if (cfg->freefall_duration & LSM6_FREE_FALL_DUR5_BIT) {
		wake_dur |= LSM6_WAKE_UP_DUR_FF_DUR5;
	}

	err = i2c_reg_write_byte_dt(&imu_i2c, LSM6_REG_WAKE_UP_DUR, wake_dur);
	if (err) {
		LOG_ERR("Failed to write WAKE_UP_DUR (err %d)", err);
		return err;
	}

	err = i2c_reg_write_byte_dt(&imu_i2c, LSM6_REG_FREE_FALL,
				    ((cfg->freefall_duration & LSM6_FREE_FALL_DUR_MASK)
				     << LSM6_FREE_FALL_DUR_SHIFT) |
					    (cfg->freefall_threshold & LSM6_FREE_FALL_THS_MASK));
	if (err) {
		LOG_ERR("Failed to write FREE_FALL (err %d)", err);
		return err;
	}

	md1 = LSM6_MD1_CFG_INT1_WU | LSM6_MD1_CFG_INT1_FF;
	if (cfg->inactivity_mode != IMU_INACTIVITY_OFF) {
		md1 |= LSM6_MD1_CFG_INT1_INACT_STATE;
	}
	if (cfg->detect_single_tap) {
		md1 |= LSM6_MD1_CFG_INT1_SINGLE_TAP;
	}
	if (cfg->detect_double_tap) {
		md1 |= LSM6_MD1_CFG_INT1_DOUBLE_TAP;
	}

	err = i2c_reg_write_byte_dt(&imu_i2c, LSM6_REG_MD1_CFG, md1);
	if (err) {
		LOG_ERR("Failed to route interrupts to INT1 (err %d)", err);
		return err;
	}

	err = gpio_pin_configure_dt(&imu_int, GPIO_INPUT);
	if (err) {
		LOG_ERR("Failed to configure IMU interrupt pin (err %d)", err);
		return err;
	}

	err = gpio_pin_interrupt_configure_dt(&imu_int, GPIO_INT_EDGE_TO_ACTIVE);
	if (err) {
		LOG_ERR("Failed to configure IMU interrupt (err %d)", err);
		return err;
	}

	gpio_init_callback(&imu_int_cb_data, imu_int_isr, BIT(imu_int.pin));

	err = gpio_add_callback_dt(&imu_int, &imu_int_cb_data);
	if (err) {
		LOG_ERR("Failed to add IMU interrupt callback (err %d)", err);
		return err;
	}

	LOG_INF("Motion detection enabled (wake ths %u dur %u; tap ths %u, single %s double %s)",
		cfg->wake_threshold, cfg->wake_duration, cfg->tap_threshold,
		cfg->detect_single_tap ? "on" : "off",
		cfg->detect_double_tap ? "on" : "off");

	return 0;
}
```

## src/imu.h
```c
/*
 * SPDX-License-Identifier: LicenseRef-Nordic-5-Clause
 */

/** @file
 *  @brief LSM6DS3TR-C accelerometer and gyroscope sampling.
 */

#ifndef IMU_H_
#define IMU_H_

#include <stdbool.h>
#include <stdint.h>

/* ------------------------------------------------------------------------
 * Motion detection.
 *
 * The Zephyr LSM6DSL driver only implements SENSOR_TRIG_DATA_READY, so the
 * wake-up, tap and free-fall engines are not reachable through the sensor API.
 * They are configured here by writing the chip's registers directly over the
 * same I2C bus, and INT1 is taken as a plain GPIO interrupt.
 *
 * This only works while the driver is built with CONFIG_LSM6DSL_TRIGGER_NONE:
 * otherwise the driver claims irq-gpios for its own data-ready handler.
 *
 * Register map: LSM6DS3TR-C datasheet, register-compatible with the LSM6DSL.
 * ------------------------------------------------------------------------ */

#define LSM6_REG_WAKE_UP_SRC		 0x1B
#define LSM6_WAKE_UP_SRC_FF_IA		 BIT(5)
#define LSM6_WAKE_UP_SRC_SLEEP_STATE_IA	 BIT(4)
#define LSM6_WAKE_UP_SRC_WU_IA		 BIT(3)

#define LSM6_REG_TAP_SRC 0x1C
#define LSM6_TAP_SRC_SINGLE_TAP BIT(5)
#define LSM6_TAP_SRC_DOUBLE_TAP BIT(4)

#define LSM6_REG_TAP_CFG 0x58
#define LSM6_TAP_CFG_INTERRUPTS_ENABLE BIT(7)
#define LSM6_TAP_CFG_INACT_EN_SHIFT    5
#define LSM6_TAP_CFG_INACT_EN_MASK     0x03
#define LSM6_TAP_CFG_SLOPE_FDS	       BIT(4)
#define LSM6_TAP_CFG_TAP_X_EN	       BIT(3)
#define LSM6_TAP_CFG_TAP_Y_EN	       BIT(2)
#define LSM6_TAP_CFG_TAP_Z_EN	       BIT(1)
#define LSM6_TAP_CFG_LIR	       BIT(0)

#define LSM6_REG_TAP_THS_6D   0x59
#define LSM6_TAP_THS_6D_MASK  0x1F

/* DUR = double-tap window, QUIET = dead time after a peak, SHOCK = maximum
 * duration of the peak itself. 0x7F is the value ST's own examples use and it
 * works for a tap through a plastic enclosure.
 */
#define LSM6_REG_INT_DUR2	0x5A
#define LSM6_INT_DUR2_DEFAULT	0x7F

#define LSM6_REG_WAKE_UP_THS		 0x5B
#define LSM6_WAKE_UP_THS_MASK		 0x3F
#define LSM6_WAKE_UP_THS_SINGLE_DOUBLE_TAP BIT(7)

/* FF_DUR is split across two registers: the low five bits sit at 7:3 here, the
 * sixth is WAKE_UP_DUR bit 7. Note that the Zephyr driver header carries a
 * FREE_FALL duration shift of 4 while its own mask covers bits 7:3 - the driver
 * never touches free fall, so the inconsistency has gone unnoticed. 3 is right.
 */
#define LSM6_REG_FREE_FALL	  0x5D
#define LSM6_FREE_FALL_DUR_SHIFT  3
#define LSM6_FREE_FALL_DUR_MASK	  0x1F
#define LSM6_FREE_FALL_THS_MASK	  0x07
#define LSM6_FREE_FALL_DUR5_BIT	  BIT(5)

#define LSM6_REG_WAKE_UP_DUR	     0x5C
#define LSM6_WAKE_UP_DUR_FF_DUR5     BIT(7)
#define LSM6_WAKE_UP_DUR_WAKE_SHIFT  5
#define LSM6_WAKE_UP_DUR_WAKE_MASK   0x03
#define LSM6_WAKE_UP_DUR_SLEEP_MASK  0x0F

#define LSM6_REG_MD1_CFG 0x5E
#define LSM6_MD1_CFG_INT1_INACT_STATE BIT(7)
#define LSM6_MD1_CFG_INT1_SINGLE_TAP BIT(6)
#define LSM6_MD1_CFG_INT1_WU	     BIT(5)
#define LSM6_MD1_CFG_INT1_FF	     BIT(4)
#define LSM6_MD1_CFG_INT1_DOUBLE_TAP BIT(3)
/** One filtered IMU reading. */
struct imu_sample {
	double accel[3];	/**< Acceleration, m/s^2, X/Y/Z. */
	double gyro[3];		/**< Angular velocity, rad/s, X/Y/Z. */
	int64_t uptime_ms;	/**< k_uptime_get() when the sample was taken. */
};

/** Events the LSM6DS3TR-C interrupt engine can raise on its INT1 pin. */
enum imu_event {
	IMU_EVENT_WAKE_UP,	/**< Acceleration crossed the wake-up threshold. */
	IMU_EVENT_INACTIVE,	/**< Nothing moved for the configured period. */
	IMU_EVENT_SINGLE_TAP,
	IMU_EVENT_DOUBLE_TAP,
	IMU_EVENT_FREE_FALL,
};

/** What the sensor does to itself once it decides nothing is moving.
 *
 *  In every mode except OFF the accelerometer drops to 12.5 Hz on its own and
 *  climbs back up when motion resumes, without the MCU being involved.
 */
enum imu_inactivity_mode {
	IMU_INACTIVITY_OFF = 0,
	IMU_INACTIVITY_ACCEL_LOW_RATE = 1,	/**< Accelerometer to 12.5 Hz. */
	IMU_INACTIVITY_GYRO_SLEEP = 2,		/**< ... and gyroscope to sleep. */
	IMU_INACTIVITY_GYRO_OFF = 3,		/**< ... and gyroscope powered down. */
};

/** Motion event callback.
 *
 *  Invoked from the system work queue - never from interrupt context - because
 *  identifying the event needs an I2C read.
 */
typedef void (*imu_event_cb_t)(enum imu_event event);

/** Tuning for the sensor's on-chip detection engines. */
struct imu_motion_config {
	/** Wake-up threshold, 0-63, in units of full-scale/64. At the +/-2 g
	 *  full scale one step is about 31 mg: 2 fires on a nudge, 8 needs a
	 *  deliberate movement, 16 needs a real shake.
	 */
	uint8_t wake_threshold;
	/** Consecutive samples that must stay above the threshold, 0-3. Each
	 *  step is one accelerometer period (about 10 ms at 104 Hz). Raising
	 *  this rejects single knocks and vibration far better than raising the
	 *  threshold alone.
	 */
	uint8_t wake_duration;
	/** Tap threshold, 0-31, in units of full-scale/32 (about 62 mg per step
	 *  at +/-2 g). Around 12 suits a tap through a plastic case.
	 */
	uint8_t tap_threshold;
	/** Report single taps.
	 *
	 *  Note that a double tap always trips the single-tap detector first, so
	 *  enabling both means every double tap also produces a single-tap
	 *  event. Leave this off if only double taps are wanted.
	 */
	bool detect_single_tap;
	/** Report double taps. */
	bool detect_double_tap;
	/** Free-fall threshold, 0-7, selecting from the sensor's fixed table of
	 *  roughly 156 mg (0) to 500 mg (7). Lower means the tag has to be
	 *  closer to true weightlessness, which cuts false positives but misses
	 *  short or tumbling drops.
	 */
	uint8_t freefall_threshold;
	/** How many accelerometer periods free fall must last, 0-63. One step is
	 *  about 10 ms at 104 Hz, so 6 is roughly 60 ms. Note this scales with
	 *  the output data rate, which inactivity_mode may lower.
	 */
	uint8_t freefall_duration;
	/** What the sensor should do once it declares inactivity. */
	enum imu_inactivity_mode inactivity_mode;
	/** How long everything must stay below the wake-up threshold before
	 *  inactivity is declared, 0-15. One step is 512 accelerometer periods,
	 *  so about 4.9 s at 104 Hz; 0 means roughly 150 ms.
	 */
	uint8_t inactivity_duration;
};

/** Turn on the sensor's own detection engines and route them to INT1.
 *
 *  The accelerometer keeps running inside the sensor and only raises the pin
 *  when something happens, so the MCU does not have to poll to notice motion.
 */
int imu_motion_detect_enable(imu_event_cb_t cb, const struct imu_motion_config *cfg);

/** Copy the most recent filtered sample.
 *
 *  This is the seam a gesture or activity classifier should read from, rather
 *  than talking to the sensor driver directly.
 *
 *  @retval 0        Sample copied.
 *  @retval -EAGAIN  No sample taken yet.
 */
int imu_get_latest(struct imu_sample *out);

/** True once the sensor has been probed successfully. */
bool imu_is_ready(void);

#endif /* IMU_H_ */
```
